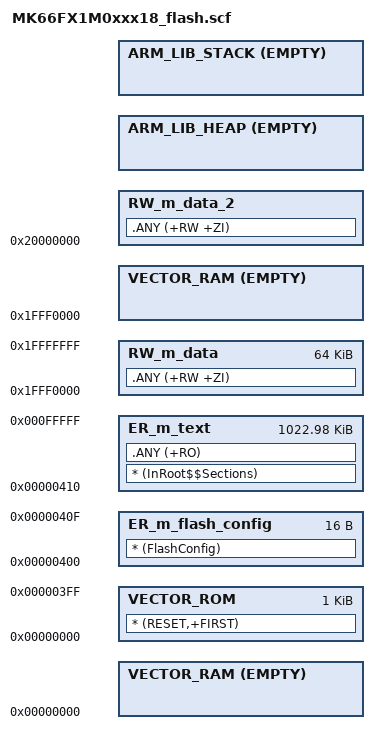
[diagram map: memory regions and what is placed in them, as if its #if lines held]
/*###ICF### Section handled by ICF editor, don't touch! ****/
/*-Editor annotation file-*/
/*-北京龙邱智能科技有限公司2016-08-23配置-*/
/* IcfEditorFile="$TOOLKIT_DIR$\config\ide\IcfEditor\cortex_v1_0.xml" */
/*-Specials-*/
define symbol __ICFEDIT_intvec_start__ = 0x1fff0000;
/*-Memory Regions-*/
define symbol __ICFEDIT_region_ROM_start__ = 0x0;
define symbol __ICFEDIT_region_ROM_end__   = 0x0;
define symbol __ICFEDIT_region_RAM_start__ = 0x1fff0000;
define symbol __ICFEDIT_region_RAM_end__   = 0x20030000;
/*-Sizes-*/
define symbol __ICFEDIT_size_cstack__ = 0x1000;
define symbol __ICFEDIT_size_heap__   = 0x2000;
/**** End of ICF editor section. ###ICF###*/

define symbol __region_RAM2_start__ = 0x20000000;
define symbol __region_RAM2_end__ = 0x20030000;

define exported symbol __VECTOR_TABLE = 0x1fff0000;
define exported symbol __VECTOR_RAM = 0x1fff0000;

define exported symbol __BOOT_STACK_ADDRESS = __region_RAM2_end__ - 8;	//0x2002FFF8;

define symbol __code_start__ = 0x1fff0410;

define memory mem with size = 4G;
define region ROM_region   = mem:[from __ICFEDIT_region_ROM_start__   to __ICFEDIT_region_ROM_end__];
define region RAM_region   = mem:[from __ICFEDIT_region_RAM_start__   to __ICFEDIT_region_RAM_end__] | mem:[from __region_RAM2_start__ to __region_RAM2_end__];

define block CSTACK    with alignment = 8, size = __ICFEDIT_size_cstack__   { };
define block HEAP      with alignment = 8, size = __ICFEDIT_size_heap__     { };

initialize manually { readwrite };
initialize manually { section .data};
initialize manually { section .textrw };
do not initialize  { section .noinit };

define block CodeRelocate { section .textrw_init };
define block CodeRelocateRam { section .textrw };


place at address mem:__ICFEDIT_intvec_start__ { readonly section .intvec };
place at address mem:__code_start__ { readonly section .noinit };

place in RAM_region   { readonly, block CodeRelocate };

place in RAM_region   { readwrite, block CodeRelocateRam,
                        block CSTACK, block HEAP };  #define __ram_vector_table_size__    0x00000400
#else
  #define __ram_vector_table_size__    0x00000000
#endif

#define m_interrupts_start             0x00000000
#define m_interrupts_size              0x00000400

#define m_flash_config_start           0x00000400
#define m_flash_config_size            0x00000010

#define m_text_start                   0x00000410
#define m_text_size                    0x000FFBF0

#define m_interrupts_ram_start         0x1FFF0000
#define m_interrupts_ram_size          __ram_vector_table_size__

#define m_data_start                   (m_interrupts_ram_start + m_interrupts_ram_size)
#define m_data_size                    (0x00010000 - m_interrupts_ram_size)

#define m_data_2_start                 0x20000000
#define m_data_2_size                  0x00030000

/* Sizes */
#if (defined(__stack_size__))
  #define Stack_Size                   __stack_size__
#else
  #define Stack_Size                   0x0400
#endif

#if (defined(__heap_size__))
  #define Heap_Size                    __heap_size__
#else
  #define Heap_Size                    0x0400
#endif

LR_m_text m_text_start m_text_size {   ; load region size_region
  ER_m_text m_text_start m_text_size { ; load address = execution address
    * (InRoot$$Sections)
    .ANY (+RO)
  }
  RW_m_data m_data_start m_data_size { ; RW data
    .ANY (+RW +ZI)
  }
  RW_m_data_2 m_data_2_start m_data_2_size-Stack_Size-Heap_Size { ; RW data
    .ANY (+RW +ZI)
  }
  ARM_LIB_HEAP ((ImageLimit(RW_m_data_2) == m_data_2_start) ? ImageLimit(RW_m_data) : +0) EMPTY Heap_Size { ; Heap region growing up
  }
  ARM_LIB_STACK m_data_2_start+m_data_2_size EMPTY -Stack_Size { ; Stack region growing down
  }
}

LR_m_interrupts m_interrupts_start m_interrupts_size {
#if (!defined(__ram_vector_table__))
  VECTOR_RAM m_interrupts_start EMPTY 0 {
  }
#endif
  VECTOR_ROM m_interrupts_start m_interrupts_size { ; load address = execution address
    * (RESET,+FIRST)
  }
}

LR_m_flash_config m_flash_config_start m_flash_config_size {
  ER_m_flash_config m_flash_config_start m_flash_config_size { ; load address = execution address
    * (FlashConfig)
  }
}

#if (defined(__ram_vector_table__))
LR_m_interrupts_ram m_interrupts_ram_start m_interrupts_ram_size {
  VECTOR_RAM m_interrupts_ram_start EMPTY m_interrupts_ram_size {
  }
}
#endif

